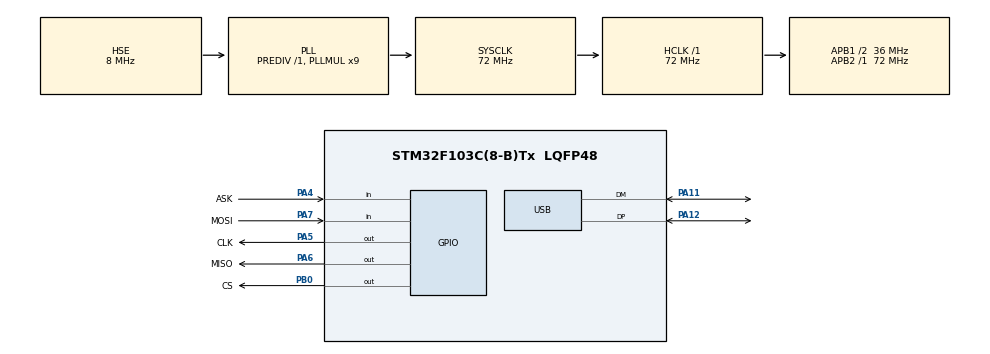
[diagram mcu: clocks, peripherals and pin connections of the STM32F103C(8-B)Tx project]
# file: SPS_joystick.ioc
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Mcu.Family=STM32F1
USB_DEVICE.CLASS_NAME_FS=HID
FREERTOS.Tasks01=defaultTask,24,128,StartDefaultTask,Default,NULL,Dynamic,NULL,NULL
PD1-OSC_OUT.Mode=HSE-External-Oscillator
USB_DEVICE.VirtualModeFS=Hid_FS
RCC.USBPrescaler=RCC_USBCLKSOURCE_PLL_DIV1_5
PA11.Mode=Device
PA6.GPIO_Label=MISO
PB0.GPIO_Label=CS
PD0-OSC_IN.Signal=RCC_OSC_IN
RCC.APB1CLKDivider=RCC_HCLK_DIV2
RCC.SYSCLKSource=RCC_SYSCLKSOURCE_PLLCLK
ProjectManager.StackSize=0x1200
VP_FREERTOS_VS_CMSIS_V2.Mode=CMSIS_V2
PD1-OSC_OUT.Signal=RCC_OSC_OUT
PA13.Signal=SYS_JTMS-SWDIO
PA12.Signal=USB_DP
VP_SYS_VS_tim3.Mode=TIM3
ProjectManager.TargetToolchain=Makefile
PB0.PinState=GPIO_PIN_SET
RCC.HCLKFreq_Value=72000000
RCC.APB2TimFreq_Value=72000000
RCC.USBFreq_Value=48000000
RCC.AHBFreq_Value=72000000
PD0-OSC_IN.Mode=HSE-External-Oscillator
PA5.Signal=GPIO_Output
PB3.Mode=Trace_Asynchronous_SW
board=custom
RCC.PLLMUL=RCC_PLL_MUL9
NVIC.TIM3_IRQn=true\:0\:0\:false\:false\:true\:false\:false\:true
VP_USB_DEVICE_VS_USB_DEVICE_HID_FS.Mode=HID_FS
RCC.APB2Freq_Value=72000000
VP_TIM2_VS_ClockSourceINT.Mode=Internal
PA14.Mode=Trace_Asynchronous_SW
NVIC.USB_LP_CAN1_RX0_IRQn=true\:5\:0\:false\:false\:true\:true\:false\:true
TIM2.Period=0xffff-1
PA13.Mode=Trace_Asynchronous_SW
Mcu.Name=STM32F103C(8-B)Tx
PB3.Signal=SYS_JTDO-TRACESWO
PA4.Signal=GPIO_Input
RCC.SYSCLKFreq_VALUE=72000000
Mcu.Package=LQFP48
TIM2.Prescaler=72-1
PA6.Signal=GPIO_Output
PA7.GPIO_Label=MOSI
NVIC.TimeBase=TIM3_IRQn
PA12.Mode=Device
PA5.GPIO_Label=CLK
PA11.Signal=USB_DM
NVIC.TimeBaseIP=TIM3
PA14.Signal=SYS_JTCK-SWCLK
ProjectManager.HeapSize=0x800
NVIC.PriorityGroup=NVIC_PRIORITYGROUP_4
RCC.APB1TimFreq_Value=72000000
RCC.APB1Freq_Value=36000000
PB0.Signal=GPIO_Output
USB_DEVICE.VirtualMode=Hid
PA4.GPIO_Label=ASK
PA7.Signal=GPIO_Input

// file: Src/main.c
/* USER CODE BEGIN Header */
/**
  ******************************************************************************
  * @file           : main.c
  * @brief          : Main program body
  ******************************************************************************
  * @attention
  *
  * <h2><center>&copy; Copyright (c) 2021 STMicroelectronics.
  * All rights reserved.</center></h2>
  *
  * This software component is licensed by ST under Ultimate Liberty license
  * SLA0044, the "License"; You may not use this file except in compliance with
  * the License. You may obtain a copy of the License at:
  *                             www.st.com/SLA0044
  *
  ******************************************************************************
  */
 /*
 * STM32F103C8T6 aka BluePill USB to PS2 wireless gamepad adapter by MadMax
 * configure GPIOs in main.h file and make
 * default GPIOs is:
 * ATT(CS) - B0;
 * DAT(stmMOSI) - A7;
 * CMD(stmMISO) - A6;
 * CLK - A5;
 * ASK - A4;
 * BluePill led - C13;
/* USER CODE END Header */

#include "main.h"
#include "cmsis_os.h"
#include "usb_device.h"
#include "PS2X_lib.h"
#include "usbd_hid.h"

TIM_HandleTypeDef htim2;

/* Definitions for defaultTask */
osThreadId_t defaultTaskHandle;
const osThreadAttr_t defaultTask_attributes = {
  .name = "defaultTask",
  .priority = (osPriority_t) osPriorityNormal,
  .stack_size = 128 * 4
};
/* USER CODE BEGIN PV */
uint16_t captured_value[8] = {0};
uint16_t rc_data[5] = {0};
uint8_t pointer = 0;
uint8_t data_ready = 0;
int error = 0;

//#define pressures   true
#define pressures   false
#define rumble      true
//#define rumble      false

USBD_HandleTypeDef hUsbDeviceFS;

/* USER CODE END PV */

void SystemClock_Config(void);
static void MX_GPIO_Init(void);
static void MX_TIM2_Init(void);
void StartDefaultTask(void *argument);

/* USER CODE BEGIN PFP */
void GetPsData(void);
/* USER CODE END PFP */

int main(void)
{

  /* MCU Configuration--------------------------------------------------------*/

  /* Reset of all peripherals, Initializes the Flash interface and the Systick. */
  HAL_Init();

  /* Configure the system clock */
  SystemClock_Config();

  /* Initialize all configured peripherals */
  MX_GPIO_Init();
  MX_TIM2_Init();
  /* USER CODE BEGIN 2 */
  HAL_Delay(100);// Some timeout
  MX_USB_DEVICE_Init();

  /* USER CODE END 2 */

  /* Init scheduler */
  osKernelInitialize();

  /* Create the thread(s) */
  /* creation of defaultTask */
  defaultTaskHandle = osThreadNew(StartDefaultTask, NULL, &defaultTask_attributes);

  /* Start scheduler */
  osKernelStart();

  /* We should never get here as control is now taken by the scheduler */
  /* Infinite loop */
  while (1)
  {

  }
}

void SystemClock_Config(void)
{
  RCC_OscInitTypeDef RCC_OscInitStruct = {0};
  RCC_ClkInitTypeDef RCC_ClkInitStruct = {0};
  RCC_PeriphCLKInitTypeDef PeriphClkInit = {0};

  /** Initializes the CPU, AHB and APB busses clocks
  */
  RCC_OscInitStruct.OscillatorType = RCC_OSCILLATORTYPE_HSE;
  RCC_OscInitStruct.HSEState = RCC_HSE_ON;
  RCC_OscInitStruct.HSEPredivValue = RCC_HSE_PREDIV_DIV1;
  RCC_OscInitStruct.HSIState = RCC_HSI_ON;
  RCC_OscInitStruct.PLL.PLLState = RCC_PLL_ON;
  RCC_OscInitStruct.PLL.PLLSource = RCC_PLLSOURCE_HSE;
  RCC_OscInitStruct.PLL.PLLMUL = RCC_PLL_MUL9;
  if (HAL_RCC_OscConfig(&RCC_OscInitStruct) != HAL_OK)
  {
    Error_Handler();
  }
  /** Initializes the CPU, AHB and APB busses clocks
  */
  RCC_ClkInitStruct.ClockType = RCC_CLOCKTYPE_HCLK|RCC_CLOCKTYPE_SYSCLK
                              |RCC_CLOCKTYPE_PCLK1|RCC_CLOCKTYPE_PCLK2;
  RCC_ClkInitStruct.SYSCLKSource = RCC_SYSCLKSOURCE_PLLCLK;
  RCC_ClkInitStruct.AHBCLKDivider = RCC_SYSCLK_DIV1;
  RCC_ClkInitStruct.APB1CLKDivider = RCC_HCLK_DIV2;
  RCC_ClkInitStruct.APB2CLKDivider = RCC_HCLK_DIV1;

  if (HAL_RCC_ClockConfig(&RCC_ClkInitStruct, FLASH_LATENCY_2) != HAL_OK)
  {
    Error_Handler();
  }
  PeriphClkInit.PeriphClockSelection = RCC_PERIPHCLK_USB;
  PeriphClkInit.UsbClockSelection = RCC_USBCLKSOURCE_PLL_DIV1_5;
  if (HAL_RCCEx_PeriphCLKConfig(&PeriphClkInit) != HAL_OK)
  {
    Error_Handler();
  }
}

static void MX_TIM2_Init(void)
{

  TIM_ClockConfigTypeDef sClockSourceConfig = {0};
  TIM_MasterConfigTypeDef sMasterConfig = {0};

  htim2.Instance = TIM2;
  htim2.Init.Prescaler = 72-1;
  htim2.Init.CounterMode = TIM_COUNTERMODE_UP;
  htim2.Init.Period = 0xffff-1;
  htim2.Init.ClockDivision = TIM_CLOCKDIVISION_DIV1;
  htim2.Init.AutoReloadPreload = TIM_AUTORELOAD_PRELOAD_DISABLE;
  if (HAL_TIM_Base_Init(&htim2) != HAL_OK)
  {
    Error_Handler();
  }
  sClockSourceConfig.ClockSource = TIM_CLOCKSOURCE_INTERNAL;
  if (HAL_TIM_ConfigClockSource(&htim2, &sClockSourceConfig) != HAL_OK)
  {
    Error_Handler();
  }
  sMasterConfig.MasterOutputTrigger = TIM_TRGO_RESET;
  sMasterConfig.MasterSlaveMode = TIM_MASTERSLAVEMODE_DISABLE;
  if (HAL_TIMEx_MasterConfigSynchronization(&htim2, &sMasterConfig) != HAL_OK)
  {
    Error_Handler();
  }
  /* USER CODE BEGIN TIM2_Init 2 */
HAL_TIM_Base_Start(&htim2);
HAL_TIM_Base_Start_IT(&htim2);
  /* USER CODE END TIM2_Init 2 */

}

static void MX_GPIO_Init(void)
{
  GPIO_InitTypeDef GPIO_InitStruct = {0};

  /* GPIO Ports Clock Enable */
  __HAL_RCC_GPIOD_CLK_ENABLE();
  __HAL_RCC_GPIOA_CLK_ENABLE();
  __HAL_RCC_GPIOB_CLK_ENABLE();
  __HAL_RCC_GPIOC_CLK_ENABLE();

  /*Configure GPIO pin Output Level */
  HAL_GPIO_WritePin(CLK_GPIO_Port, CLK_Pin|MISO_Pin, GPIO_PIN_RESET);

  /*Configure GPIO pin Output Level */
  HAL_GPIO_WritePin(CS_GPIO_Port, CS_Pin, GPIO_PIN_RESET);
  HAL_GPIO_WritePin(LED_Port, LED_Pin, GPIO_PIN_SET);

  /*Configure GPIO pins : ASK_Pin  */
  GPIO_InitStruct.Pin = ASK_Pin;
  GPIO_InitStruct.Mode = GPIO_MODE_INPUT;
  GPIO_InitStruct.Pull = GPIO_PULLUP;
  HAL_GPIO_Init(CLK_GPIO_Port, &GPIO_InitStruct);

    GPIO_InitStruct.Pin = MOSI_Pin;
  GPIO_InitStruct.Mode = GPIO_MODE_INPUT;
  GPIO_InitStruct.Pull = GPIO_PULLUP;
  HAL_GPIO_Init(CLK_GPIO_Port, &GPIO_InitStruct);

  /*Configure GPIO pins : CLK_Pin */
  GPIO_InitStruct.Pin = CLK_Pin;
  GPIO_InitStruct.Mode = GPIO_MODE_OUTPUT_PP;
  GPIO_InitStruct.Pull = GPIO_NOPULL;
  GPIO_InitStruct.Speed = GPIO_SPEED_FREQ_LOW;
  HAL_GPIO_Init(CLK_GPIO_Port, &GPIO_InitStruct);

    /*Configure GPIO pins : MISO_Pin */
  GPIO_InitStruct.Pin = MISO_Pin;
  GPIO_InitStruct.Mode = GPIO_MODE_OUTPUT_PP;
  GPIO_InitStruct.Pull = GPIO_NOPULL;
  GPIO_InitStruct.Speed = GPIO_SPEED_FREQ_LOW;
  HAL_GPIO_Init(CLK_GPIO_Port, &GPIO_InitStruct);

  /*Configure GPIO pin : CS_Pin */
  GPIO_InitStruct.Pin = CS_Pin;
  GPIO_InitStruct.Mode = GPIO_MODE_OUTPUT_PP;
  GPIO_InitStruct.Pull = GPIO_NOPULL;
  GPIO_InitStruct.Speed = GPIO_SPEED_FREQ_LOW;
  HAL_GPIO_Init(CS_GPIO_Port, &GPIO_InitStruct);

    /*Configure LED pin : PC13 */
  GPIO_InitStruct.Pin = LED_Pin;
  GPIO_InitStruct.Mode = GPIO_MODE_OUTPUT_PP;
  GPIO_InitStruct.Pull = GPIO_NOPULL;
  GPIO_InitStruct.Speed = GPIO_SPEED_FREQ_LOW;
  HAL_GPIO_Init(LED_Port , &GPIO_InitStruct);

}

/* USER CODE BEGIN 4 */
void GetPsData(void)
{
  //rc_data[0] = PS2data[1];
  rc_data[0] = Analog(PSS_LX); //Left stick, Y axis. Other options: LX, RY, RX
  rc_data[1] = Analog(PSS_LY);
  rc_data[2] = Analog(PSS_RY);
  rc_data[3] = Analog(PSS_RX);
  //rc_data[4] = ButtonDataByte();
  rc_data[4] = (uint16_t)(PS2data[4] << 8) + PS2data[3];
}

void delayMicroseconds (uint16_t us)
{
	__HAL_TIM_SET_COUNTER(&htim2,0);  // set the counter value a 0
	while (__HAL_TIM_GET_COUNTER(&htim2) < us);  // wait for the counter to reach the us input in the parameter
}
/* USER CODE END 4 */

void StartDefaultTask(void *argument)
{
  /* init code for USB_DEVICE */
  //MX_USB_DEVICE_Init();
  /* USER CODE BEGIN 5 */
while(true)
{
      error = config_gamepad(0, 0, 0, 0, pressures, rumble);
      if(!error)
      {
        HAL_GPIO_WritePin(LED_Port, LED_Pin, GPIO_PIN_RESET);
        break;
      }
      //Blink while GamePad init
      HAL_GPIO_WritePin(LED_Port, LED_Pin, GPIO_PIN_RESET);
      osDelay(200);
      HAL_GPIO_WritePin(LED_Port, LED_Pin, GPIO_PIN_SET);
}
  /* Infinite loop */
  int cntr = 10;
  for(;;)
  {
    if(cntr)
    {
      data_ready = read_gamepad(false, 0x40);
      cntr--;
    }
    else
    {
      data_ready = read_gamepad(false, 0x00);
    }

    GetPsData();
    USBD_HID_SendReport(&hUsbDeviceFS, (uint8_t*)rc_data, 10);
    osDelay(1);
  }
  /* USER CODE END 5 */
}

 /**
  * @brief  Period elapsed callback in non blocking mode
  * @note   This function is called  when TIM3 interrupt took place, inside
  * HAL_TIM_IRQHandler(). It makes a direct call to HAL_IncTick() to increment
  * a global variable "uwTick" used as application time base.
  * @param  htim : TIM handle
  * @retval None
  */
void HAL_TIM_PeriodElapsedCallback(TIM_HandleTypeDef *htim)
{
  if (htim->Instance == TIM3) {
    HAL_IncTick();
  }
}

void Error_Handler(void)
{
}

/************************ (C) COPYRIGHT STMicroelectronics *****END OF FILE****/
